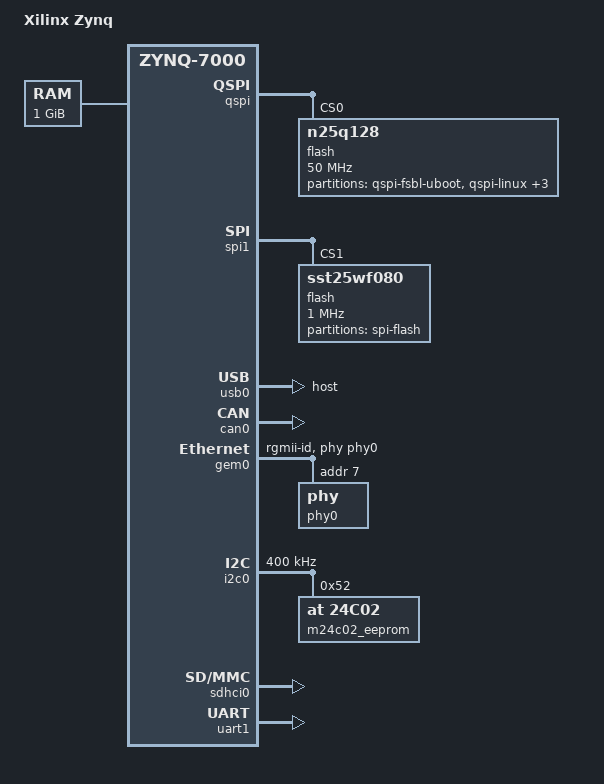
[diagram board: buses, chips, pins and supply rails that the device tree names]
/*
 * Device Tree Generator version: 1.1
 *
 * (C) Copyright 2007-2013 Xilinx, Inc.
 * (C) Copyright 2007-2013 Michal Simek
 * (C) Copyright 2007-2012 PetaLogix Qld Pty Ltd
 *
 * Michal SIMEK <monstr@monstr.eu>
 *
 * CAUTION: This file is automatically generated by libgen.
 * Version: Xilinx EDK 14.5 EDK_P.58f
 *
 */
/dts-v1/;
/include/ "zynq-7000.dtsi"

/ {
	compatible = "xlnx,zynq-zc770-xm010", "xlnx,zynq-7000";
	model = "Xilinx Zynq";

	aliases {
		ethernet0 = &gem0;
		i2c0 = &i2c0;
		serial0 = &uart1;
		spi0 = &spi1;
		spi1 = &qspi;
	};

	chosen {
		bootargs = "console=ttyPS0,115200 root=/dev/ram rw earlyprintk";
		linux,stdout-path = "/amba/serial@e0001000";
	};

	memory@0 {
		device_type = "memory";
		reg = <0x0 0x40000000>;
	};
};

&qspi {
	status = "okay";
	is-dual = <0>;
	num-cs = <1>;
	xlnx,fb-clk = <0x1>;
	xlnx,qspi-mode = <0x0>;
	flash@0 {
		compatible = "n25q128";
		reg = <0x0>;
		spi-tx-bus-width = <1>;
		spi-rx-bus-width = <4>;
		spi-max-frequency = <50000000>;
		#address-cells = <1>;
		#size-cells = <1>;
		partition@qspi-fsbl-uboot {
			label = "qspi-fsbl-uboot";
			reg = <0x0 0x100000>;
		};
		partition@qspi-linux {
			label = "qspi-linux";
			reg = <0x100000 0x500000>;
		};
		partition@qspi-device-tree {
			label = "qspi-device-tree";
			reg = <0x600000 0x20000>;
		};
		partition@qspi-rootfs {
			label = "qspi-rootfs";
			reg = <0x620000 0x5E0000>;
		};
		partition@qspi-bitstream {
			label = "qspi-bitstream";
			reg = <0xC00000 0x400000>;
		};
	};
};

&spi1 {
	status = "okay";
	num-cs = <4>;
	is-decoded-cs = <0>;
	flash@0 {
		compatible = "sst25wf080";
		reg = <1>;
		spi-max-frequency = <1000000>;
		#address-cells = <1>;
		#size-cells = <1>;
		partition@test {
			label = "spi-flash";
			reg = <0x0 0x100000>;
		};
	};
};

&usb0 {
	status = "okay";
	dr_mode = "host";
	phy_type = "ulpi";
	usb-reset = <&gpio0 7 0>;
};

&can0 {
	status = "okay";
};

&gem0 {
	status = "okay";
	phy-mode = "rgmii-id";
	phy-handle = <&phy0>;

	phy0: phy@7 {
		reg = <7>;
	};
};

&i2c0 {
	status = "okay";
	clock-frequency = <400000>;

	m24c02_eeprom@52 {
		compatible = "at,24c02";
		reg = <0x52>;
	};

};

&sdhci0 {
	status = "okay";
};

&uart1 {
	status = "okay";
};
